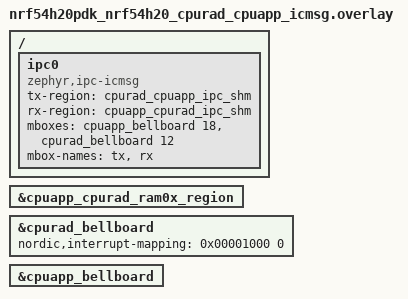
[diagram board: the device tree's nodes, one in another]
/*
 * Copyright (c) 2024 Nordic Semiconductor ASA
 * SPDX-License-Identifier: LicenseRef-Nordic-5-Clause
 */

 / {
	ipc0: ipc0 {
		compatible = "zephyr,ipc-icmsg";
		tx-region = <&cpurad_cpuapp_ipc_shm>;
		rx-region = <&cpuapp_cpurad_ipc_shm>;
		mboxes = <&cpuapp_bellboard 18>,
			 <&cpurad_bellboard 12>;
		mbox-names = "tx", "rx";
		status = "okay";
	};
};

&cpuapp_cpurad_ram0x_region {
	status = "okay";
};

&cpurad_bellboard {
	status = "okay";
	nordic,interrupt-mapping = <0x00001000 0>;
};

&cpuapp_bellboard {
	status = "okay";
};
